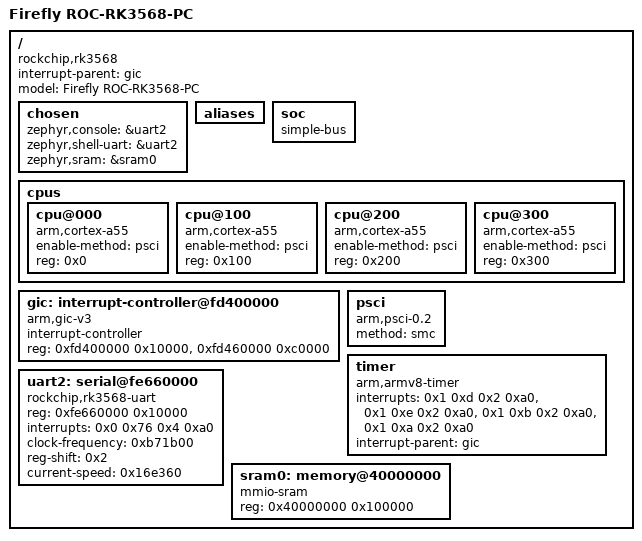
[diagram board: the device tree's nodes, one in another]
/dts-v1/;

/* node '/' defined in zephyr/dts/common/skeleton.dtsi:9 */
/ {
	#address-cells = < 0x1 >;        /* in zephyr/dts/arm64/rockchip/rk3568.dtsi:14 */
	#size-cells = < 0x1 >;           /* in zephyr/dts/arm64/rockchip/rk3568.dtsi:15 */
	interrupt-parent = < &gic >;     /* in zephyr/dts/arm64/rockchip/rk3568.dtsi:18 */
	model = "Firefly ROC-RK3568-PC"; /* in zephyr/boards/firefly/roc_rk3568_pc/roc_rk3568_pc.dts:13 */
	compatible = "rockchip,rk3568";  /* in zephyr/boards/firefly/roc_rk3568_pc/roc_rk3568_pc.dts:14 */

	/* node '/chosen' defined in zephyr/dts/common/skeleton.dtsi:13 */
	chosen {
		zephyr,console = &uart2;    /* in zephyr/boards/firefly/roc_rk3568_pc/roc_rk3568_pc.dts:17 */
		zephyr,shell-uart = &uart2; /* in zephyr/boards/firefly/roc_rk3568_pc/roc_rk3568_pc.dts:18 */
		zephyr,sram = &sram0;       /* in zephyr/boards/firefly/roc_rk3568_pc/roc_rk3568_pc.dts:19 */
	};

	/* node '/aliases' defined in zephyr/dts/common/skeleton.dtsi:15 */
	aliases {
	};

	/* node '/soc' defined in zephyr/dts/arm64/armv8-a.dtsi:10 */
	soc {
		#address-cells = < 0x1 >;  /* in zephyr/dts/arm64/armv8-a.dtsi:11 */
		#size-cells = < 0x1 >;     /* in zephyr/dts/arm64/armv8-a.dtsi:12 */
		compatible = "simple-bus"; /* in zephyr/dts/arm64/armv8-a.dtsi:13 */
		ranges;                    /* in zephyr/dts/arm64/armv8-a.dtsi:14 */
	};

	/* node '/cpus' defined in zephyr/dts/arm64/rockchip/rk3568.dtsi:20 */
	cpus {
		#address-cells = < 0x1 >; /* in zephyr/dts/arm64/rockchip/rk3568.dtsi:21 */
		#size-cells = < 0x0 >;    /* in zephyr/dts/arm64/rockchip/rk3568.dtsi:22 */

		/* node '/cpus/cpu@000' defined in zephyr/dts/arm64/rockchip/rk3568.dtsi:24 */
		cpu@000 {
			device_type = "cpu";           /* in zephyr/dts/arm64/rockchip/rk3568.dtsi:25 */
			compatible = "arm,cortex-a55"; /* in zephyr/dts/arm64/rockchip/rk3568.dtsi:26 */
			enable-method = "psci";        /* in zephyr/dts/arm64/rockchip/rk3568.dtsi:27 */
			reg = < 0x0 >;                 /* in zephyr/dts/arm64/rockchip/rk3568.dtsi:28 */
		};

		/* node '/cpus/cpu@100' defined in zephyr/dts/arm64/rockchip/rk3568.dtsi:31 */
		cpu@100 {
			device_type = "cpu";           /* in zephyr/dts/arm64/rockchip/rk3568.dtsi:32 */
			compatible = "arm,cortex-a55"; /* in zephyr/dts/arm64/rockchip/rk3568.dtsi:33 */
			enable-method = "psci";        /* in zephyr/dts/arm64/rockchip/rk3568.dtsi:34 */
			reg = < 0x100 >;               /* in zephyr/dts/arm64/rockchip/rk3568.dtsi:35 */
		};

		/* node '/cpus/cpu@200' defined in zephyr/dts/arm64/rockchip/rk3568.dtsi:38 */
		cpu@200 {
			device_type = "cpu";           /* in zephyr/dts/arm64/rockchip/rk3568.dtsi:39 */
			compatible = "arm,cortex-a55"; /* in zephyr/dts/arm64/rockchip/rk3568.dtsi:40 */
			enable-method = "psci";        /* in zephyr/dts/arm64/rockchip/rk3568.dtsi:41 */
			reg = < 0x200 >;               /* in zephyr/dts/arm64/rockchip/rk3568.dtsi:42 */
		};

		/* node '/cpus/cpu@300' defined in zephyr/dts/arm64/rockchip/rk3568.dtsi:45 */
		cpu@300 {
			device_type = "cpu";           /* in zephyr/dts/arm64/rockchip/rk3568.dtsi:46 */
			compatible = "arm,cortex-a55"; /* in zephyr/dts/arm64/rockchip/rk3568.dtsi:47 */
			enable-method = "psci";        /* in zephyr/dts/arm64/rockchip/rk3568.dtsi:48 */
			reg = < 0x300 >;               /* in zephyr/dts/arm64/rockchip/rk3568.dtsi:49 */
		};
	};

	/* node '/interrupt-controller@fd400000' defined in zephyr/dts/arm64/rockchip/rk3568.dtsi:53 */
	gic: interrupt-controller@fd400000 {
		#address-cells = < 0x1 >;     /* in zephyr/dts/arm64/rockchip/rk3568.dtsi:54 */
		compatible = "arm,gic-v3",
		             "arm,gic";       /* in zephyr/dts/arm64/rockchip/rk3568.dtsi:55 */
		#interrupt-cells = < 0x4 >;   /* in zephyr/dts/arm64/rockchip/rk3568.dtsi:56 */
		interrupt-controller;         /* in zephyr/dts/arm64/rockchip/rk3568.dtsi:57 */
		reg = < 0xfd400000 0x10000 >,
		      < 0xfd460000 0xc0000 >; /* in zephyr/dts/arm64/rockchip/rk3568.dtsi:59 */
		status = "okay";              /* in zephyr/dts/arm64/rockchip/rk3568.dtsi:61 */
		phandle = < 0x1 >;            /* in zephyr/dts/arm64/rockchip/rk3568.dtsi:18 */
	};

	/* node '/psci' defined in zephyr/dts/arm64/rockchip/rk3568.dtsi:64 */
	psci {
		compatible = "arm,psci-0.2",
		             "arm,psci";     /* in zephyr/dts/arm64/rockchip/rk3568.dtsi:65 */
		method = "smc";              /* in zephyr/dts/arm64/rockchip/rk3568.dtsi:66 */
	};

	/* node '/timer' defined in zephyr/dts/arm64/rockchip/rk3568.dtsi:69 */
	timer {
		compatible = "arm,armv8-timer";    /* in zephyr/dts/arm64/rockchip/rk3568.dtsi:70 */
		interrupts = < 0x1 0xd 0x2 0xa0 >,
		             < 0x1 0xe 0x2 0xa0 >,
		             < 0x1 0xb 0x2 0xa0 >,
		             < 0x1 0xa 0x2 0xa0 >; /* in zephyr/dts/arm64/rockchip/rk3568.dtsi:71 */
		interrupt-parent = < &gic >;       /* in zephyr/dts/arm64/rockchip/rk3568.dtsi:75 */
	};

	/* node '/serial@fe660000' defined in zephyr/dts/arm64/rockchip/rk3568.dtsi:78 */
	uart2: serial@fe660000 {
		compatible = "rockchip,rk3568-uart",
		             "ns16550";              /* in zephyr/dts/arm64/rockchip/rk3568.dtsi:79 */
		reg = < 0xfe660000 0x10000 >;        /* in zephyr/dts/arm64/rockchip/rk3568.dtsi:80 */
		interrupts = < 0x0 0x76 0x4 0xa0 >;  /* in zephyr/dts/arm64/rockchip/rk3568.dtsi:81 */
		clock-frequency = < 0xb71b00 >;      /* in zephyr/dts/arm64/rockchip/rk3568.dtsi:82 */
		reg-shift = < 0x2 >;                 /* in zephyr/dts/arm64/rockchip/rk3568.dtsi:83 */
		status = "okay";                     /* in zephyr/boards/firefly/roc_rk3568_pc/roc_rk3568_pc.dts:30 */
		current-speed = < 0x16e360 >;        /* in zephyr/boards/firefly/roc_rk3568_pc/roc_rk3568_pc.dts:31 */
	};

	/* node '/memory@40000000' defined in zephyr/boards/firefly/roc_rk3568_pc/roc_rk3568_pc.dts:22 */
	sram0: memory@40000000 {
		device_type = "memory";        /* in zephyr/boards/firefly/roc_rk3568_pc/roc_rk3568_pc.dts:23 */
		compatible = "mmio-sram";      /* in zephyr/boards/firefly/roc_rk3568_pc/roc_rk3568_pc.dts:24 */
		reg = < 0x40000000 0x100000 >; /* in zephyr/boards/firefly/roc_rk3568_pc/roc_rk3568_pc.dts:25 */
	};
};
